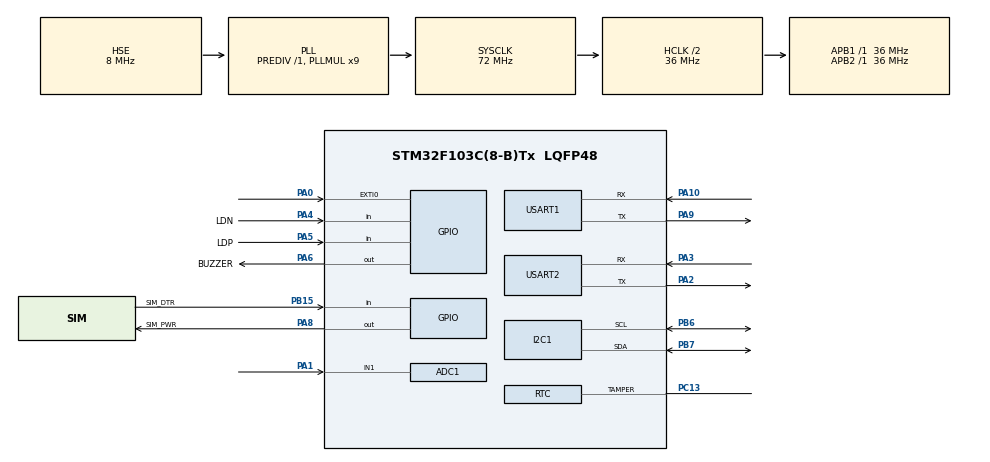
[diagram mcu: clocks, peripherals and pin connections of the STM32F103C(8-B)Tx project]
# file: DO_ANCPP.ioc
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ADC1.Channel-0\#ChannelRegularConversion=ADC_CHANNEL_1
ADC1.ContinuousConvMode=ENABLE
ADC1.NbrOfConversionFlag=1
ADC1.SamplingTime-0\#ChannelRegularConversion=ADC_SAMPLETIME_13CYCLES_5
ADC1.master=1
Dma.ADC1.1.Direction=DMA_PERIPH_TO_MEMORY
Dma.ADC1.1.Instance=DMA1_Channel1
Dma.ADC1.1.MemDataAlignment=DMA_MDATAALIGN_HALFWORD
Dma.ADC1.1.MemInc=DMA_MINC_ENABLE
Dma.ADC1.1.Mode=DMA_NORMAL
Dma.ADC1.1.PeriphDataAlignment=DMA_PDATAALIGN_HALFWORD
Dma.ADC1.1.PeriphInc=DMA_PINC_DISABLE
Dma.ADC1.1.Priority=DMA_PRIORITY_LOW
Dma.Request0=USART1_RX
Dma.Request1=ADC1
Dma.USART1_RX.0.Direction=DMA_PERIPH_TO_MEMORY
Dma.USART1_RX.0.Instance=DMA1_Channel5
Dma.USART1_RX.0.MemDataAlignment=DMA_MDATAALIGN_BYTE
Dma.USART1_RX.0.MemInc=DMA_MINC_ENABLE
Dma.USART1_RX.0.Mode=DMA_NORMAL
Dma.USART1_RX.0.PeriphDataAlignment=DMA_PDATAALIGN_BYTE
Dma.USART1_RX.0.PeriphInc=DMA_PINC_DISABLE
Dma.USART1_RX.0.Priority=DMA_PRIORITY_LOW
Mcu.Family=STM32F1
Mcu.Name=STM32F103C(8-B)Tx
Mcu.Package=LQFP48
NVIC.DMA1_Channel1_IRQn=true\:0\:0\:false\:false\:true\:false\:true\:true
NVIC.DMA1_Channel5_IRQn=true\:0\:0\:false\:false\:true\:false\:true\:true
NVIC.EXTI0_IRQn=true\:10\:0\:true\:false\:true\:true\:true\:true
NVIC.PriorityGroup=NVIC_PRIORITYGROUP_4
NVIC.RTC_IRQn=true\:0\:0\:false\:false\:true\:true\:true\:true
NVIC.TIM2_IRQn=true\:0\:0\:false\:false\:true\:true\:true\:true
NVIC.TIM3_IRQn=true\:0\:0\:false\:false\:true\:true\:true\:true
NVIC.TIM4_IRQn=true\:0\:0\:false\:false\:true\:true\:true\:true
NVIC.USART1_IRQn=true\:0\:0\:false\:false\:true\:true\:true\:true
PA0-WKUP.GPIO_ModeDefaultEXTI=GPIO_MODE_IT_FALLING
PA0-WKUP.GPIO_PuPd=GPIO_PULLUP
PA0-WKUP.Signal=GPXTI0
PA1.Signal=ADCx_IN1
PA10.Mode=Asynchronous
PA10.Signal=USART1_RX
PA13.Mode=Serial_Wire
PA13.Signal=SYS_JTMS-SWDIO
PA14.Mode=Serial_Wire
PA14.Signal=SYS_JTCK-SWCLK
PA2.Mode=Asynchronous
PA2.Signal=USART2_TX
PA3.Mode=Asynchronous
PA3.Signal=USART2_RX
PA4.GPIO_Label=LDN
PA4.GPIO_PuPd=GPIO_NOPULL
PA4.Signal=GPIO_Input
PA5.GPIO_Label=LDP
PA5.GPIO_PuPd=GPIO_NOPULL
PA5.Signal=GPIO_Input
PA6.GPIO_Label=BUZZER
PA6.Signal=GPIO_Output
PA8.GPIO_Label=SIM_PWR
PA8.PinState=GPIO_PIN_SET
PA8.Signal=GPIO_Output
PA9.Mode=Asynchronous
PA9.Signal=USART1_TX
PB15.GPIO_Label=SIM_DTR
PB15.Signal=GPIO_Input
PB6.GPIO_Speed=GPIO_SPEED_FREQ_HIGH
PB6.Mode=I2C
PB6.Signal=I2C1_SCL
PB7.GPIO_Speed=GPIO_SPEED_FREQ_HIGH
PB7.Mode=I2C
PB7.Signal=I2C1_SDA
PC13-TAMPER-RTC.Mode=Tamper
PC13-TAMPER-RTC.Signal=RTC_TAMPER
PD0-OSC_IN.Mode=HSE-External-Oscillator
PD0-OSC_IN.Signal=RCC_OSC_IN
PD1-OSC_OUT.Mode=HSE-External-Oscillator
PD1-OSC_OUT.Signal=RCC_OSC_OUT
ProjectManager.HeapSize=0x2000
ProjectManager.StackSize=0x4000
ProjectManager.TargetToolchain=STM32CubeIDE
RCC.ADCPresc=RCC_ADCPCLK2_DIV4
RCC.AHBCLKDivider=RCC_SYSCLK_DIV2
RCC.AHBFreq_Value=36000000
RCC.APB1Freq_Value=36000000
RCC.APB1TimFreq_Value=36000000
RCC.APB2Freq_Value=36000000
RCC.APB2TimFreq_Value=36000000
RCC.HCLKFreq_Value=36000000
RCC.PLLMUL=RCC_PLL_MUL9
RCC.PLLSourceVirtual=RCC_PLLSOURCE_HSE
RCC.SYSCLKFreq_VALUE=72000000
RCC.SYSCLKSource=RCC_SYSCLKSOURCE_PLLCLK
RCC.USBFreq_Value=72000000
RTC.Format=RTC_FORMAT_BIN
SH.ADCx_IN1.0=ADC1_IN1,IN1
TIM2.Period=50000
TIM2.Prescaler=43200
TIM3.Period=1999
TIM3.Prescaler=359
TIM4.Period=12000
TIM4.Prescaler=12000
USART1.VirtualMode=VM_ASYNC
USART2.VirtualMode=VM_ASYNC
VP_RTC_VS_RTC_Activate.Mode=RTC_Enabled
VP_RTC_VS_RTC_Calendar.Mode=RTC_Calendar
VP_TIM2_VS_ClockSourceINT.Mode=Internal
VP_TIM3_VS_ClockSourceINT.Mode=Internal
VP_TIM4_VS_ClockSourceINT.Mode=Internal
board=custom

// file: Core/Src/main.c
/* USER CODE BEGIN Header */
/**
  ******************************************************************************
  * @file           : main.c
  * @brief          : Main program body
  ******************************************************************************
  * @attention
  *
  * Copyright (c) 2023 STMicroelectronics.
  * All rights reserved.
  *
  * This software is licensed under terms that can be found in the LICENSE file
  * in the root directory of this software component.
  * If no LICENSE file comes with this software, it is provided AS-IS.
  *
  ******************************************************************************
  */
/* USER CODE END Header */
#include "main.h"

/* USER CODE BEGIN Includes */
#include "stdio.h"
#include "myMain.hpp"
/* USER CODE END Includes */

ADC_HandleTypeDef hadc1;
DMA_HandleTypeDef hdma_adc1;

I2C_HandleTypeDef hi2c1;

RTC_HandleTypeDef hrtc;

TIM_HandleTypeDef htim2;
TIM_HandleTypeDef htim3;
TIM_HandleTypeDef htim4;

UART_HandleTypeDef huart1;
UART_HandleTypeDef huart2;
DMA_HandleTypeDef hdma_usart1_rx;

void SystemClock_Config(void);
static void MX_GPIO_Init(void);
static void MX_DMA_Init(void);
static void MX_USART1_UART_Init(void);
static void MX_USART2_UART_Init(void);
static void MX_ADC1_Init(void);
static void MX_TIM3_Init(void);
static void MX_I2C1_Init(void);
static void MX_TIM2_Init(void);
static void MX_TIM4_Init(void);
static void MX_RTC_Init(void);

/* USER CODE BEGIN 0 */
int _write(int file, char *ptr, int len)
{
	HAL_UART_Transmit(&huart2, (uint8_t *)ptr, len, 1000);
	return len;
}
/* USER CODE END 0 */

int main(void)
{

  /* MCU Configuration--------------------------------------------------------*/

  /* Reset of all peripherals, Initializes the Flash interface and the Systick. */
  HAL_Init();

  /* Configure the system clock */
  SystemClock_Config();

  /* Initialize all configured peripherals */
  MX_GPIO_Init();
  MX_DMA_Init();
  MX_USART1_UART_Init();
  MX_USART2_UART_Init();
  MX_ADC1_Init();
  MX_TIM3_Init();
  MX_I2C1_Init();
  MX_TIM2_Init();
  MX_TIM4_Init();
  MX_RTC_Init();
  /* USER CODE BEGIN 2 */
  printf("HAL_I2C_IsDeviceReady:%d\r\n",HAL_I2C_IsDeviceReady(&hi2c1, 0xAE, 10, 100));
  initC();
  /* USER CODE END 2 */

  /* Infinite loop */
  /* USER CODE BEGIN WHILE */
  while (1)
  {
	  loopC();
    /* USER CODE END WHILE */

  }
}

void SystemClock_Config(void)
{
  RCC_OscInitTypeDef RCC_OscInitStruct = {0};
  RCC_ClkInitTypeDef RCC_ClkInitStruct = {0};
  RCC_PeriphCLKInitTypeDef PeriphClkInit = {0};

  /** Initializes the RCC Oscillators according to the specified parameters
  * in the RCC_OscInitTypeDef structure.
  */
  RCC_OscInitStruct.OscillatorType = RCC_OSCILLATORTYPE_LSI|RCC_OSCILLATORTYPE_HSE;
  RCC_OscInitStruct.HSEState = RCC_HSE_ON;
  RCC_OscInitStruct.HSEPredivValue = RCC_HSE_PREDIV_DIV1;
  RCC_OscInitStruct.HSIState = RCC_HSI_ON;
  RCC_OscInitStruct.LSIState = RCC_LSI_ON;
  RCC_OscInitStruct.PLL.PLLState = RCC_PLL_ON;
  RCC_OscInitStruct.PLL.PLLSource = RCC_PLLSOURCE_HSE;
  RCC_OscInitStruct.PLL.PLLMUL = RCC_PLL_MUL9;
  if (HAL_RCC_OscConfig(&RCC_OscInitStruct) != HAL_OK)
  {
    Error_Handler();
  }

  /** Initializes the CPU, AHB and APB buses clocks
  */
  RCC_ClkInitStruct.ClockType = RCC_CLOCKTYPE_HCLK|RCC_CLOCKTYPE_SYSCLK
                              |RCC_CLOCKTYPE_PCLK1|RCC_CLOCKTYPE_PCLK2;
  RCC_ClkInitStruct.SYSCLKSource = RCC_SYSCLKSOURCE_PLLCLK;
  RCC_ClkInitStruct.AHBCLKDivider = RCC_SYSCLK_DIV2;
  RCC_ClkInitStruct.APB1CLKDivider = RCC_HCLK_DIV1;
  RCC_ClkInitStruct.APB2CLKDivider = RCC_HCLK_DIV1;

  if (HAL_RCC_ClockConfig(&RCC_ClkInitStruct, FLASH_LATENCY_2) != HAL_OK)
  {
    Error_Handler();
  }
  PeriphClkInit.PeriphClockSelection = RCC_PERIPHCLK_RTC|RCC_PERIPHCLK_ADC;
  PeriphClkInit.RTCClockSelection = RCC_RTCCLKSOURCE_LSI;
  PeriphClkInit.AdcClockSelection = RCC_ADCPCLK2_DIV4;
  if (HAL_RCCEx_PeriphCLKConfig(&PeriphClkInit) != HAL_OK)
  {
    Error_Handler();
  }
}

static void MX_ADC1_Init(void)
{

  ADC_ChannelConfTypeDef sConfig = {0};

  /** Common config
  */
  hadc1.Instance = ADC1;
  hadc1.Init.ScanConvMode = ADC_SCAN_DISABLE;
  hadc1.Init.ContinuousConvMode = ENABLE;
  hadc1.Init.DiscontinuousConvMode = DISABLE;
  hadc1.Init.ExternalTrigConv = ADC_SOFTWARE_START;
  hadc1.Init.DataAlign = ADC_DATAALIGN_RIGHT;
  hadc1.Init.NbrOfConversion = 1;
  if (HAL_ADC_Init(&hadc1) != HAL_OK)
  {
    Error_Handler();
  }

  /** Configure Regular Channel
  */
  sConfig.Channel = ADC_CHANNEL_1;
  sConfig.Rank = ADC_REGULAR_RANK_1;
  sConfig.SamplingTime = ADC_SAMPLETIME_13CYCLES_5;
  if (HAL_ADC_ConfigChannel(&hadc1, &sConfig) != HAL_OK)
  {
    Error_Handler();
  }

}

static void MX_I2C1_Init(void)
{

  hi2c1.Instance = I2C1;
  hi2c1.Init.ClockSpeed = 100000;
  hi2c1.Init.DutyCycle = I2C_DUTYCYCLE_2;
  hi2c1.Init.OwnAddress1 = 0;
  hi2c1.Init.AddressingMode = I2C_ADDRESSINGMODE_7BIT;
  hi2c1.Init.DualAddressMode = I2C_DUALADDRESS_DISABLE;
  hi2c1.Init.OwnAddress2 = 0;
  hi2c1.Init.GeneralCallMode = I2C_GENERALCALL_DISABLE;
  hi2c1.Init.NoStretchMode = I2C_NOSTRETCH_DISABLE;
  if (HAL_I2C_Init(&hi2c1) != HAL_OK)
  {
    Error_Handler();
  }

}

static void MX_RTC_Init(void)
{

  RTC_TimeTypeDef sTime = {0};
  RTC_DateTypeDef DateToUpdate = {0};
  RTC_TamperTypeDef sTamper = {0};

  /** Initialize RTC Only
  */
  hrtc.Instance = RTC;
  hrtc.Init.AsynchPrediv = RTC_AUTO_1_SECOND;
  hrtc.Init.OutPut = RTC_OUTPUTSOURCE_NONE;
  if (HAL_RTC_Init(&hrtc) != HAL_OK)
  {
    Error_Handler();
  }

  /** Initialize RTC and set the Time and Date
  */
  sTime.Hours = 0;
  sTime.Minutes = 0;
  sTime.Seconds = 0;

  if (HAL_RTC_SetTime(&hrtc, &sTime, RTC_FORMAT_BIN) != HAL_OK)
  {
    Error_Handler();
  }
  DateToUpdate.WeekDay = RTC_WEEKDAY_MONDAY;
  DateToUpdate.Month = RTC_MONTH_JANUARY;
  DateToUpdate.Date = 1;
  DateToUpdate.Year = 0;

  if (HAL_RTC_SetDate(&hrtc, &DateToUpdate, RTC_FORMAT_BIN) != HAL_OK)
  {
    Error_Handler();
  }

  /** Enable the RTC Tamper
  */
  sTamper.Tamper = RTC_TAMPER_1;
  sTamper.Trigger = RTC_TAMPERTRIGGER_LOWLEVEL;
  if (HAL_RTCEx_SetTamper(&hrtc, &sTamper) != HAL_OK)
  {
    Error_Handler();
  }

}

static void MX_TIM2_Init(void)
{

  TIM_ClockConfigTypeDef sClockSourceConfig = {0};
  TIM_MasterConfigTypeDef sMasterConfig = {0};

  htim2.Instance = TIM2;
  htim2.Init.Prescaler = 43200;
  htim2.Init.CounterMode = TIM_COUNTERMODE_UP;
  htim2.Init.Period = 50000;
  htim2.Init.ClockDivision = TIM_CLOCKDIVISION_DIV1;
  htim2.Init.AutoReloadPreload = TIM_AUTORELOAD_PRELOAD_DISABLE;
  if (HAL_TIM_Base_Init(&htim2) != HAL_OK)
  {
    Error_Handler();
  }
  sClockSourceConfig.ClockSource = TIM_CLOCKSOURCE_INTERNAL;
  if (HAL_TIM_ConfigClockSource(&htim2, &sClockSourceConfig) != HAL_OK)
  {
    Error_Handler();
  }
  sMasterConfig.MasterOutputTrigger = TIM_TRGO_RESET;
  sMasterConfig.MasterSlaveMode = TIM_MASTERSLAVEMODE_DISABLE;
  if (HAL_TIMEx_MasterConfigSynchronization(&htim2, &sMasterConfig) != HAL_OK)
  {
    Error_Handler();
  }

}

static void MX_TIM3_Init(void)
{

  TIM_ClockConfigTypeDef sClockSourceConfig = {0};
  TIM_MasterConfigTypeDef sMasterConfig = {0};

  htim3.Instance = TIM3;
  htim3.Init.Prescaler = 359;
  htim3.Init.CounterMode = TIM_COUNTERMODE_UP;
  htim3.Init.Period = 1999;
  htim3.Init.ClockDivision = TIM_CLOCKDIVISION_DIV1;
  htim3.Init.AutoReloadPreload = TIM_AUTORELOAD_PRELOAD_DISABLE;
  if (HAL_TIM_Base_Init(&htim3) != HAL_OK)
  {
    Error_Handler();
  }
  sClockSourceConfig.ClockSource = TIM_CLOCKSOURCE_INTERNAL;
  if (HAL_TIM_ConfigClockSource(&htim3, &sClockSourceConfig) != HAL_OK)
  {
    Error_Handler();
  }
  sMasterConfig.MasterOutputTrigger = TIM_TRGO_RESET;
  sMasterConfig.MasterSlaveMode = TIM_MASTERSLAVEMODE_DISABLE;
  if (HAL_TIMEx_MasterConfigSynchronization(&htim3, &sMasterConfig) != HAL_OK)
  {
    Error_Handler();
  }

}

static void MX_TIM4_Init(void)
{

  TIM_ClockConfigTypeDef sClockSourceConfig = {0};
  TIM_MasterConfigTypeDef sMasterConfig = {0};

  htim4.Instance = TIM4;
  htim4.Init.Prescaler = 12000;
  htim4.Init.CounterMode = TIM_COUNTERMODE_UP;
  htim4.Init.Period = 12000;
  htim4.Init.ClockDivision = TIM_CLOCKDIVISION_DIV1;
  htim4.Init.AutoReloadPreload = TIM_AUTORELOAD_PRELOAD_DISABLE;
  if (HAL_TIM_Base_Init(&htim4) != HAL_OK)
  {
    Error_Handler();
  }
  sClockSourceConfig.ClockSource = TIM_CLOCKSOURCE_INTERNAL;
  if (HAL_TIM_ConfigClockSource(&htim4, &sClockSourceConfig) != HAL_OK)
  {
    Error_Handler();
  }
  sMasterConfig.MasterOutputTrigger = TIM_TRGO_RESET;
  sMasterConfig.MasterSlaveMode = TIM_MASTERSLAVEMODE_DISABLE;
  if (HAL_TIMEx_MasterConfigSynchronization(&htim4, &sMasterConfig) != HAL_OK)
  {
    Error_Handler();
  }

}

static void MX_USART1_UART_Init(void)
{

  huart1.Instance = USART1;
  huart1.Init.BaudRate = 115200;
  huart1.Init.WordLength = UART_WORDLENGTH_8B;
  huart1.Init.StopBits = UART_STOPBITS_1;
  huart1.Init.Parity = UART_PARITY_NONE;
  huart1.Init.Mode = UART_MODE_TX_RX;
  huart1.Init.HwFlowCtl = UART_HWCONTROL_NONE;
  huart1.Init.OverSampling = UART_OVERSAMPLING_16;
  if (HAL_UART_Init(&huart1) != HAL_OK)
  {
    Error_Handler();
  }

}

static void MX_USART2_UART_Init(void)
{

  huart2.Instance = USART2;
  huart2.Init.BaudRate = 115200;
  huart2.Init.WordLength = UART_WORDLENGTH_8B;
  huart2.Init.StopBits = UART_STOPBITS_1;
  huart2.Init.Parity = UART_PARITY_NONE;
  huart2.Init.Mode = UART_MODE_TX_RX;
  huart2.Init.HwFlowCtl = UART_HWCONTROL_NONE;
  huart2.Init.OverSampling = UART_OVERSAMPLING_16;
  if (HAL_UART_Init(&huart2) != HAL_OK)
  {
    Error_Handler();
  }

}

static void MX_DMA_Init(void)
{

  /* DMA controller clock enable */
  __HAL_RCC_DMA1_CLK_ENABLE();

  /* DMA interrupt init */
  /* DMA1_Channel1_IRQn interrupt configuration */
  HAL_NVIC_SetPriority(DMA1_Channel1_IRQn, 0, 0);
  HAL_NVIC_EnableIRQ(DMA1_Channel1_IRQn);
  /* DMA1_Channel5_IRQn interrupt configuration */
  HAL_NVIC_SetPriority(DMA1_Channel5_IRQn, 0, 0);
  HAL_NVIC_EnableIRQ(DMA1_Channel5_IRQn);

}

static void MX_GPIO_Init(void)
{
  GPIO_InitTypeDef GPIO_InitStruct = {0};

  /* GPIO Ports Clock Enable */
  __HAL_RCC_GPIOC_CLK_ENABLE();
  __HAL_RCC_GPIOD_CLK_ENABLE();
  __HAL_RCC_GPIOA_CLK_ENABLE();
  __HAL_RCC_GPIOB_CLK_ENABLE();

  /*Configure GPIO pin Output Level */
  HAL_GPIO_WritePin(BUZZER_GPIO_Port, BUZZER_Pin, GPIO_PIN_RESET);

  /*Configure GPIO pin Output Level */
  HAL_GPIO_WritePin(SIM_PWR_GPIO_Port, SIM_PWR_Pin, GPIO_PIN_SET);

  /*Configure GPIO pin : PA0 */
  GPIO_InitStruct.Pin = GPIO_PIN_0;
  GPIO_InitStruct.Mode = GPIO_MODE_IT_FALLING;
  GPIO_InitStruct.Pull = GPIO_PULLUP;
  HAL_GPIO_Init(GPIOA, &GPIO_InitStruct);

  /*Configure GPIO pins : LDN_Pin LDP_Pin */
  GPIO_InitStruct.Pin = LDN_Pin|LDP_Pin;
  GPIO_InitStruct.Mode = GPIO_MODE_INPUT;
  GPIO_InitStruct.Pull = GPIO_NOPULL;
  HAL_GPIO_Init(GPIOA, &GPIO_InitStruct);

  /*Configure GPIO pins : BUZZER_Pin SIM_PWR_Pin */
  GPIO_InitStruct.Pin = BUZZER_Pin|SIM_PWR_Pin;
  GPIO_InitStruct.Mode = GPIO_MODE_OUTPUT_PP;
  GPIO_InitStruct.Pull = GPIO_NOPULL;
  GPIO_InitStruct.Speed = GPIO_SPEED_FREQ_LOW;
  HAL_GPIO_Init(GPIOA, &GPIO_InitStruct);

  /*Configure GPIO pin : SIM_DTR_Pin */
  GPIO_InitStruct.Pin = SIM_DTR_Pin;
  GPIO_InitStruct.Mode = GPIO_MODE_INPUT;
  GPIO_InitStruct.Pull = GPIO_NOPULL;
  HAL_GPIO_Init(SIM_DTR_GPIO_Port, &GPIO_InitStruct);

  /* EXTI interrupt init*/
  HAL_NVIC_SetPriority(EXTI0_IRQn, 10, 0);
  HAL_NVIC_EnableIRQ(EXTI0_IRQn);

}

void Error_Handler(void)
{
  __disable_irq();
  while (1)
  {
  }
}
